VERSION ""

NS_ :

BS_:

BU_: XXX 0

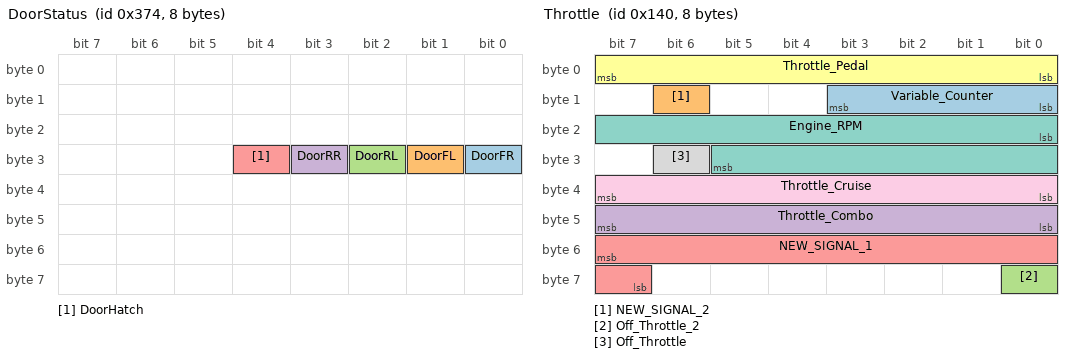
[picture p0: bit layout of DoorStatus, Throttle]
BO_ 884 DoorStatus: 8 XXX
 SG_ DoorFR : 24|1@0+ (1,0) [0|1] "" XXX
 SG_ DoorFL : 25|1@0+ (1,0) [0|1] "" XXX
 SG_ DoorRL : 26|1@0+ (1,0) [0|1] "" XXX
 SG_ DoorRR : 27|1@0+ (1,0) [0|1] "" XXX
 SG_ DoorHatch : 28|1@0+ (1,0) [0|1] "" XXX

BO_ 324 CruiseControl: 8 XXX
 SG_ NEW_SIGNAL_7 : 4|1@0+ (1,0) [0|3] "" XXX
 SG_ NEW_SIGNAL_3 : 4|1@0+ (1,0) [0|15] "" XXX
 SG_ CRUISE_SET : 3|1@0+ (1,0) [0|3] "" XXX
 SG_ NEW_SIGNAL_2 : 8|1@0+ (1,0) [0|255] "" XXX
 SG_ NEW_SIGNAL_9 : 15|1@1+ (1,0) [0|127] "" XXX
 SG_ NEW_SIGNAL_1 : 23|8@0+ (1,0) [0|255] "" XXX
 SG_ NEW_SIGNAL_6 : 50|1@0+ (1,0) [0|3] "" XXX
 SG_ Cruise_On : 48|1@0+ (1,0) [0|3] "" XXX
 SG_ OnOff : 2|1@1+ (1,0) [0|3] "" XXX
 SG_ NEW_SIGNAL_4 : 51|1@0+ (1,0) [0|3] "" XXX

BO_ 320 Throttle: 8 XXX
 SG_ Variable_Counter : 8|4@1+ (1,0) [0|15] "" XXX
 SG_ NEW_SIGNAL_2 : 14|1@0+ (1,0) [0|15] "" XXX
 SG_ Off_Throttle_2 : 56|1@1+ (1,0) [0|3] "" XXX
 SG_ Throttle_Combo : 40|8@1+ (1,0) [0|255] "" XXX
 SG_ NEW_SIGNAL_1 : 55|9@0+ (1,0) [0|255] "" XXX
 SG_ Throttle_Pedal : 0|8@1+ (0.392157,0) [0|255] "" XXX
 SG_ Engine_RPM : 16|14@1+ (1,0) [0|15] "" XXX
 SG_ Off_Throttle : 30|1@0+ (1,0) [0|3] "" XXX
 SG_ Throttle_Cruise : 39|8@0+ (1,0) [0|255] "" XXX

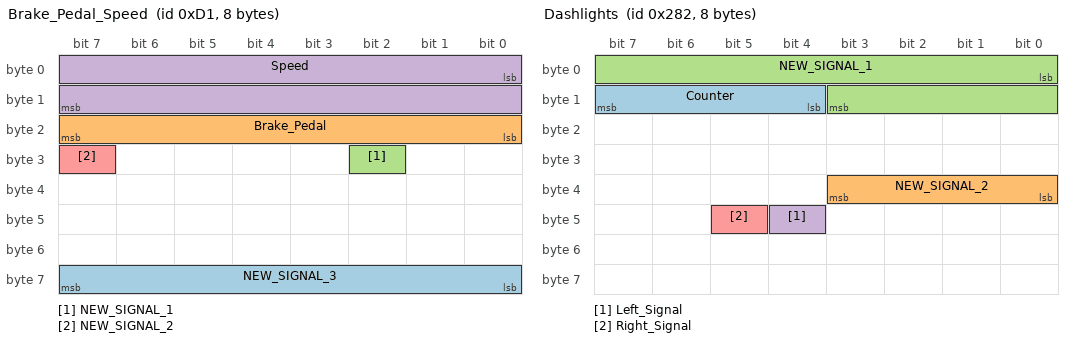
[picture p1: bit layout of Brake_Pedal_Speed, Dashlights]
BO_ 209 Brake_Pedal_Speed: 8 XXX
 SG_ NEW_SIGNAL_3 : 56|8@1+ (1,0) [0|255] "" XXX
 SG_ Brake_Pedal : 23|8@0+ (1,0) [0|255] "" XXX
 SG_ NEW_SIGNAL_1 : 26|1@1+ (1,0) [0|3] "" XXX
 SG_ Speed : 0|16@1+ (1,0) [0|255] "KPH" XXX
 SG_ NEW_SIGNAL_2 : 31|1@1+ (1,0) [0|255] "" XXX

BO_ 2 Steering: 8 XXX
 SG_ NEW_SIGNAL_1 : 31|4@0- (1,0) [0|65535] "" XXX
 SG_ SteeringAngle : 7|16@0- (0.1,0) [-497|500] "degree" XXX
 SG_ NEW_SIGNAL_3 : 33|3@1+ (1,0) [0|15] "" XXX
 SG_ NEW_SIGNAL_2 : 36|4@1+ (1,0) [0|255] "" XXX
 SG_ NEW_SIGNAL_4 : 32|1@1+ (1,0) [0|3] "" XXX
 SG_ NEW_SIGNAL_5 : 37|2@0+ (1,0) [0|3] "" XXX
 SG_ NEW_SIGNAL_6 : 24|1@1+ (1,0) [0|3] "" XXX
 SG_ Counter : 25|3@1+ (1,0) [0|15] "" XXX

BO_ 642 Dashlights: 8 XXX
 SG_ Counter : 15|4@0+ (1,0) [0|15] "" XXX
 SG_ NEW_SIGNAL_2 : 32|4@1+ (1,0) [0|15] "" XXX
 SG_ NEW_SIGNAL_1 : 0|12@1+ (1,0) [0|255] "" XXX
 SG_ Left_Signal : 44|1@0+ (1,0) [0|3] "" XXX
 SG_ Right_Signal : 45|1@0+ (1,0) [0|3] "" XXX

BO_ 112 Lateral_G: 8 XXX
 SG_ Lateral_G : 8|8@1+ (1,0) [0|15] "" XXX

BO_ 882 ES_Counter: 8 XXX
 SG_ Counter : 15|4@0+ (1,0) [0|31] "" XXX
 SG_ NEW_SIGNAL_1 : 30|1@0+ (1,0) [0|3] "" XXX

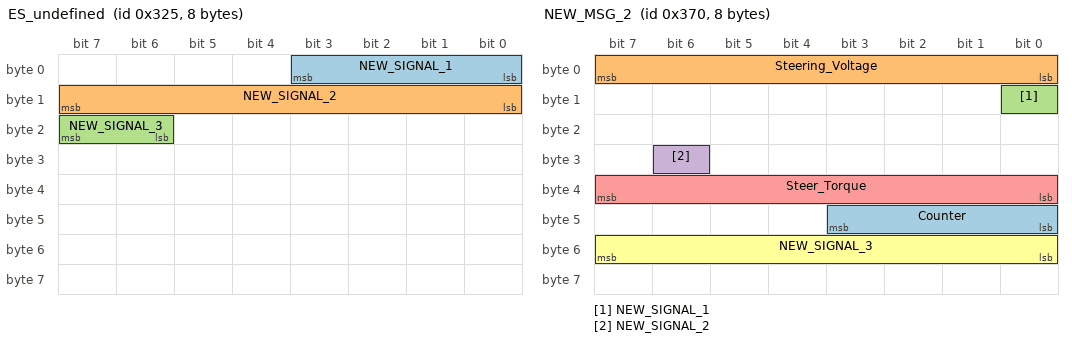
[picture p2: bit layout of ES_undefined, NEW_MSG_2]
BO_ 805 ES_undefined: 8 XXX
 SG_ NEW_SIGNAL_1 : 0|4@1+ (1,0) [0|15] "" XXX
 SG_ NEW_SIGNAL_2 : 8|8@1+ (1,0) [0|255] "" XXX
 SG_ NEW_SIGNAL_3 : 23|2@0+ (1,0) [0|3] "" XXX

BO_ 604 undefined: 8 XXX
 SG_ NEW_SIGNAL_1 : 33|1@1+ (1,0) [0|3] "" XXX
 SG_ NEW_SIGNAL_3 : 43|1@0+ (1,0) [0|3] "" XXX

BO_ 886 undefined: 8 XXX

BO_ 880 NEW_MSG_2: 8 XXX
 SG_ Counter : 40|4@1+ (1,0) [0|15] "" XXX
 SG_ Steering_Voltage : 7|8@0+ (1,0) [0|255] "" XXX
 SG_ NEW_SIGNAL_1 : 8|1@0+ (1,0) [0|255] "" XXX
 SG_ NEW_SIGNAL_2 : 30|1@0+ (1,0) [0|3] "" XXX
 SG_ Steer_Torque : 39|8@0- (1,0) [0|255] "" XXX
 SG_ NEW_SIGNAL_3 : 48|8@1+ (1,0) [0|15] "" XXX

BO_ 554 NEW_MSG_3: 8 XXX
 SG_ Counter : 0|4@1+ (1,0) [0|255] "" XXX

BO_ 355 NEW_MSG_4: 8 XXX
 SG_ Counter : 40|3@1+ (1,0) [0|7] "" XXX

BO_ 1398 NEW_MSG_5: 8 XXX
 SG_ NEW_SIGNAL_2 : 23|8@0+ (1,0) [0|255] "" XXX
 SG_ NEW_SIGNAL_1 : 39|8@0+ (1,0) [0|255] "" XXX
 SG_ NEW_SIGNAL_3 : 39|4@0+ (1,0) [0|15] "" XXX
 SG_ Steer_Torque : 0|8@1+ (1,0) [0|15] "" XXX
 SG_ NEW_SIGNAL_4 : 47|8@0+ (1,0) [0|65535] "" XXX
 SG_ NEW_SIGNAL_5 : 48|8@1+ (1,0) [0|255] "" XXX

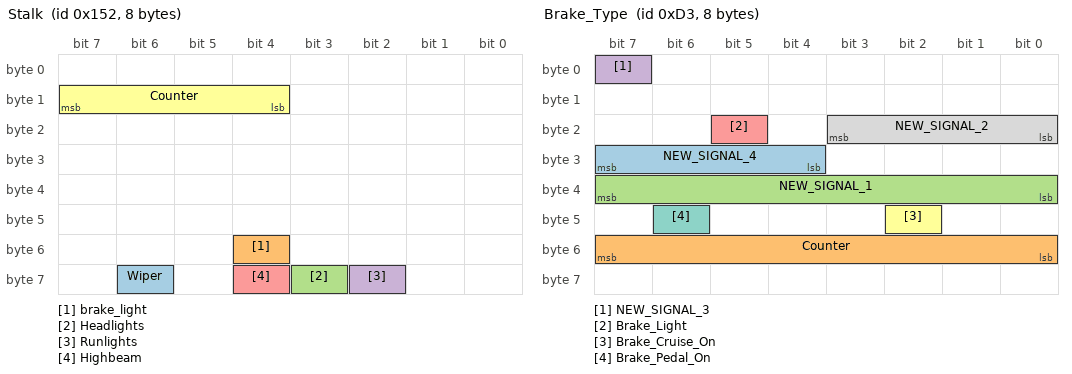
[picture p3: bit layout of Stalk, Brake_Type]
BO_ 338 Stalk: 8 XXX
 SG_ Wiper : 62|1@0+ (1,0) [0|3] "" XXX
 SG_ brake_light : 52|1@0+ (1,0) [0|3] "" XXX
 SG_ Headlights : 59|1@0+ (1,0) [0|3] "" XXX
 SG_ Runlights : 58|1@1+ (1,0) [0|3] "" XXX
 SG_ Highbeam : 60|1@0+ (1,0) [0|3] "" XXX
 SG_ Counter : 15|4@0+ (1,0) [0|15] "" XXX

BO_ 211 Brake_Type: 8 XXX
 SG_ NEW_SIGNAL_4 : 28|4@1+ (1,0) [0|15] "" XXX
 SG_ Counter : 55|8@0+ (1,0) [0|255] "" XXX
 SG_ NEW_SIGNAL_1 : 32|8@1+ (1,0) [0|15] "" XXX
 SG_ NEW_SIGNAL_3 : 7|1@0+ (1,0) [0|4294967295] "" XXX
 SG_ Brake_Light : 21|1@0+ (1,0) [0|3] "" XXX
 SG_ Brake_Cruise_On : 42|1@0+ (1,0) [0|3] "" XXX
 SG_ Brake_Pedal_On : 46|1@0+ (1,0) [0|3] "" XXX
 SG_ NEW_SIGNAL_2 : 16|4@1+ (1,0) [0|15] "" XXX

BO_ 321 undefined: 8 XXX
 SG_ NEW_SIGNAL_1 : 0|16@1+ (1,0) [0|255] "" XXX
 SG_ NEW_SIGNAL_4 : 16|16@1+ (1,0) [0|255] "" XXX
 SG_ NEW_SIGNAL_7 : 59|2@1+ (1,0) [0|63] "" XXX
 SG_ NEW_SIGNAL_8 : 32|12@1+ (1,0) [0|8191] "" XXX
 SG_ NEW_SIGNAL_6 : 46|1@0+ (1,0) [0|3] "" XXX
 SG_ NEW_SIGNAL_2 : 47|1@1+ (1,0) [0|15] "" XXX
 SG_ NEW_SIGNAL_3 : 54|2@0+ (1,0) [0|255] "" XXX
 SG_ NEW_SIGNAL_5 : 48|4@1+ (1,0) [0|15] "" XXX

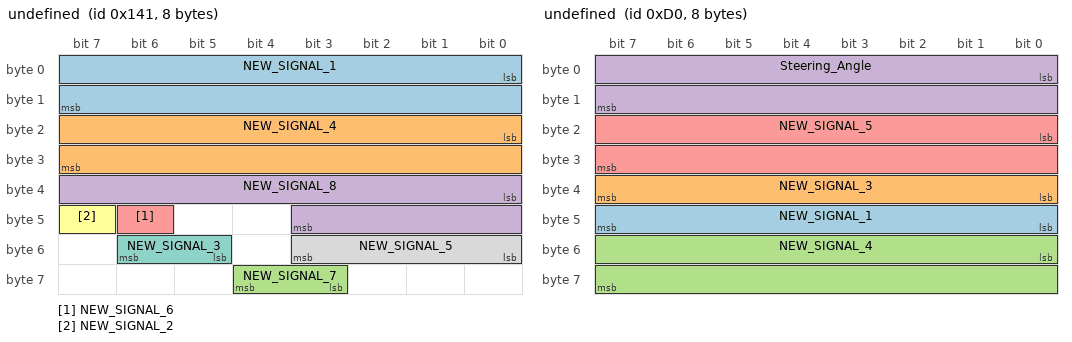
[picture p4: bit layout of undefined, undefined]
BO_ 208 undefined: 8 XXX
 SG_ NEW_SIGNAL_1 : 47|8@0+ (1,0) [0|255] "" XXX
 SG_ NEW_SIGNAL_3 : 32|8@1+ (1,0) [0|255] "" XXX
 SG_ NEW_SIGNAL_4 : 48|16@1- (1,0) [0|255] "" XXX
 SG_ Steering_Angle : 0|16@1- (1,0) [0|65535] "" XXX
 SG_ NEW_SIGNAL_5 : 16|16@1- (1,0) [0|65535] "" XXX

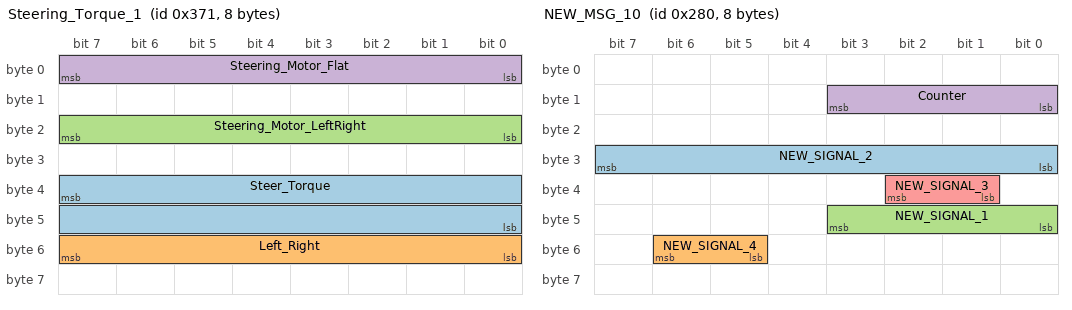
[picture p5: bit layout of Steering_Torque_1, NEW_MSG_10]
BO_ 881 Steering_Torque_1: 8 XXX
 SG_ Steer_Torque : 39|16@0- (1,0) [0|255] "" XXX
 SG_ Left_Right : 55|8@0- (1,0) [0|255] "" XXX
 SG_ Steering_Motor_LeftRight : 23|8@0- (1,0) [0|255] "" XXX
 SG_ Steering_Motor_Flat : 0|8@1+ (1,0) [0|255] "" XXX

BO_ 336 Brake_Pressure: 8 XXX
 SG_ Brake_Pressure_1 : 0|8@1+ (1,0) [0|15] "" XXX
 SG_ Brake_Pressure_2 : 15|8@0+ (1,0) [0|255] "" XXX

BO_ 640 NEW_MSG_10: 8 XXX
 SG_ NEW_SIGNAL_2 : 24|8@1+ (1,0) [0|255] "" XXX
 SG_ NEW_SIGNAL_4 : 54|2@0+ (1,0) [0|15] "" XXX
 SG_ NEW_SIGNAL_1 : 43|4@0+ (1,0) [0|255] "" XXX
 SG_ Counter : 8|4@1+ (1,0) [0|15] "" XXX
 SG_ NEW_SIGNAL_3 : 34|2@0+ (1,0) [0|63] "" XXX

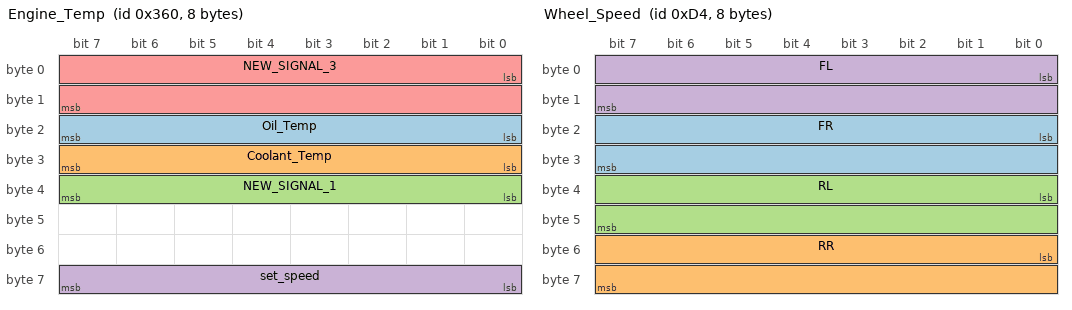
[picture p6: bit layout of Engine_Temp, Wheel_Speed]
BO_ 864 Engine_Temp: 8 XXX
 SG_ Oil_Temp : 16|8@1+ (1,-40) [0|255] "" XXX
 SG_ Coolant_Temp : 24|8@1+ (1,-40) [0|255] "" XXX
 SG_ NEW_SIGNAL_1 : 32|8@1+ (1,0) [0|255] "" XXX
 SG_ set_speed : 56|8@1+ (1,0) [0|63] "" XXX
 SG_ NEW_SIGNAL_3 : 0|16@1+ (1,0) [0|255] "" XXX

BO_ 212 Wheel_Speed: 8 XXX
 SG_ FR : 16|16@1+ (0.05747,0) [0|255] "KPH" XXX
 SG_ RR : 48|16@1+ (0.05747,0) [0|127] "KPH" XXX
 SG_ RL : 32|16@1+ (0.05747,0) [0|255] "" XXX
 SG_ FL : 0|16@1+ (0.05747,0) [2|255] "KPH" XXX

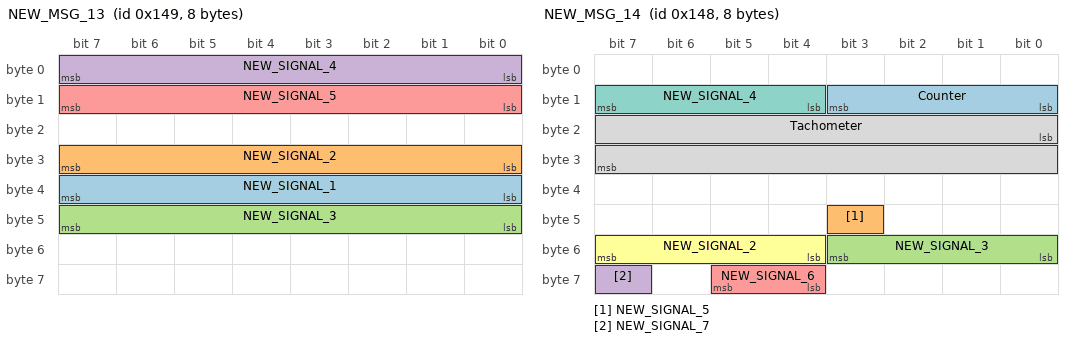
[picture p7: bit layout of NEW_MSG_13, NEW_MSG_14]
BO_ 329 NEW_MSG_13: 8 XXX
 SG_ NEW_SIGNAL_1 : 32|8@1+ (1,0) [0|255] "" XXX
 SG_ NEW_SIGNAL_2 : 31|8@0+ (1,0) [0|255] "" XXX
 SG_ NEW_SIGNAL_3 : 40|8@1+ (1,0) [0|255] "" XXX
 SG_ NEW_SIGNAL_4 : 0|8@1+ (1,0) [0|255] "" XXX
 SG_ NEW_SIGNAL_5 : 15|8@0+ (1,0) [0|65535] "" XXX

BO_ 328 NEW_MSG_14: 8 XXX
 SG_ Counter : 11|4@0+ (1,0) [0|255] "" XXX
 SG_ NEW_SIGNAL_5 : 43|1@0+ (1,0) [0|65535] "" XXX
 SG_ NEW_SIGNAL_3 : 48|4@1+ (1,0) [0|15] "" XXX
 SG_ NEW_SIGNAL_7 : 63|1@0+ (1,0) [0|3] "" XXX
 SG_ NEW_SIGNAL_6 : 60|2@1+ (1,0) [0|255] "" XXX
 SG_ NEW_SIGNAL_2 : 52|4@1+ (1,0) [0|15] "" XXX
 SG_ NEW_SIGNAL_4 : 15|4@0+ (1,0) [0|15] "" XXX
 SG_ Tachometer : 16|16@1+ (1,0) [0|65535] "" XXX

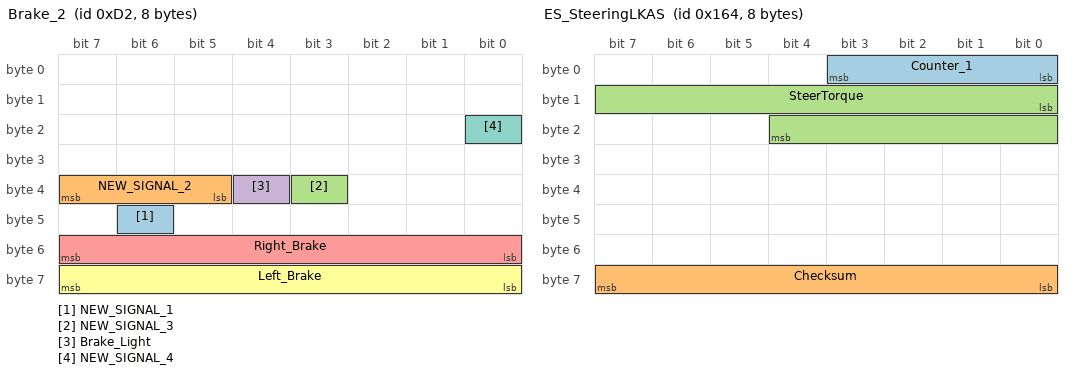
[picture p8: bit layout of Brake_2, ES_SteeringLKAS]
BO_ 210 Brake_2: 8 XXX
 SG_ NEW_SIGNAL_1 : 46|1@0+ (1,0) [0|4294967295] "" XXX
 SG_ NEW_SIGNAL_2 : 39|3@0+ (1,0) [0|7] "" XXX
 SG_ NEW_SIGNAL_3 : 35|1@1+ (1,0) [0|15] "" XXX
 SG_ Brake_Light : 36|1@1+ (1,0) [0|255] "" XXX
 SG_ Right_Brake : 48|8@1+ (1,0) [0|255] "" XXX
 SG_ Left_Brake : 63|8@0+ (1,0) [0|255] "" XXX
 SG_ NEW_SIGNAL_4 : 16|1@0+ (1,0) [0|1] "" XXX

BO_ 346 Counter_3: 8 XXX
 SG_ Counter : 0|4@1+ (1,0) [0|15] "" XXX

BO_ 356 ES_SteeringLKAS: 8 XXX
 SG_ Counter_1 : 0|4@1+ (1,0) [0|15] "" XXX
 SG_ Checksum : 56|8@1+ (1,0) [0|15] "" XXX
 SG_ SteerTorque : 8|13@1- (1,0) [0|65535] "" XXX

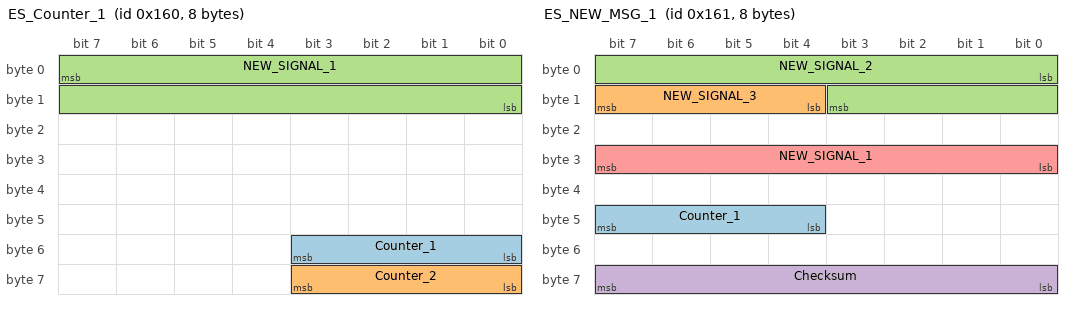
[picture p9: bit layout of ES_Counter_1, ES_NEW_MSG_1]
BO_ 352 ES_Counter_1: 8 XXX
 SG_ Counter_1 : 48|4@1+ (1,0) [0|15] "" XXX
 SG_ Counter_2 : 59|4@0+ (1,0) [0|4095] "" XXX
 SG_ NEW_SIGNAL_1 : 7|16@0+ (1,0) [0|65535] "" XXX

BO_ 392 Counter_0: 8 XXX
 SG_ Counter : 16|4@1+ (1,0) [0|15] "" XXX

BO_ 353 ES_NEW_MSG_1: 8 XXX
 SG_ Counter_1 : 47|4@0+ (1,0) [0|15] "" XXX
 SG_ NEW_SIGNAL_3 : 15|4@0+ (1,0) [0|15] "" XXX
 SG_ NEW_SIGNAL_2 : 0|12@1+ (1,0) [0|255] "" XXX
 SG_ Checksum : 56|8@1+ (1,0) [0|15] "" XXX
 SG_ NEW_SIGNAL_1 : 24|8@1+ (1,0) [0|3] "" XXX

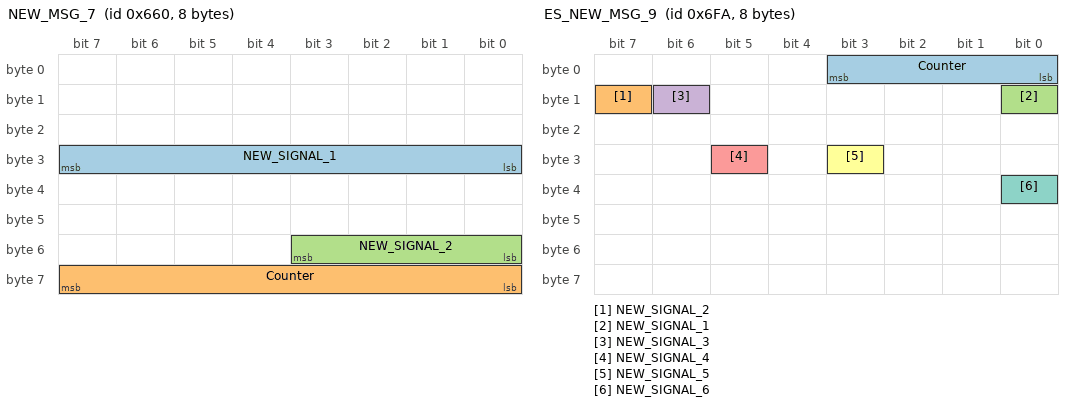
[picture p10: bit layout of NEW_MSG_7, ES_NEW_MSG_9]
BO_ 1632 NEW_MSG_7: 8 XXX
 SG_ NEW_SIGNAL_1 : 31|8@0+ (1,0) [0|255] "" XXX
 SG_ Counter : 56|8@1+ (1,0) [0|255] "" XXX
 SG_ NEW_SIGNAL_2 : 51|4@0+ (1,0) [0|16777215] "" XXX

BO_ 644 NEW_MSG_8: 8 XXX
 SG_ Counter : 8|4@1+ (1,0) [0|15] "" XXX

BO_ 1786 ES_NEW_MSG_9: 8 XXX
 SG_ Counter : 3|4@0+ (1,0) [0|255] "" XXX
 SG_ NEW_SIGNAL_2 : 15|1@1+ (1,0) [0|15] "" XXX
 SG_ NEW_SIGNAL_1 : 8|1@1+ (1,0) [0|3] "" XXX
 SG_ NEW_SIGNAL_3 : 14|1@0+ (1,0) [0|3] "" XXX
 SG_ NEW_SIGNAL_4 : 29|1@0+ (1,0) [0|1] "" XXX
 SG_ NEW_SIGNAL_5 : 27|1@1+ (1,0) [0|3] "" XXX
 SG_ NEW_SIGNAL_6 : 32|1@1+ (1,0) [0|3] "" XXX

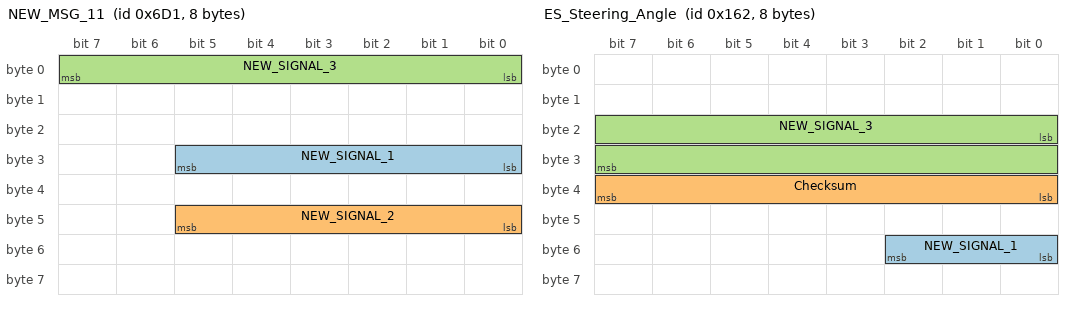
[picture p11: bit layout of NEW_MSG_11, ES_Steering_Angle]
BO_ 1745 NEW_MSG_11: 8 XXX
 SG_ NEW_SIGNAL_1 : 24|6@1+ (1,0) [0|255] "" XXX
 SG_ NEW_SIGNAL_2 : 40|6@1+ (1,0) [0|15] "" XXX
 SG_ NEW_SIGNAL_3 : 0|8@1+ (1,0) [0|255] "" XXX

BO_ 977 NEW_MSG_12: 8 XXX
 SG_ NEW_SIGNAL_1 : 0|8@1+ (1,0) [0|255] "" XXX
 SG_ NEW_SIGNAL_2 : 16|8@1+ (1,0) [0|255] "" XXX

BO_ 872 NEW_MSG_15: 8 XXX

BO_ 354 ES_Steering_Angle: 8 XXX
 SG_ NEW_SIGNAL_1 : 48|3@1+ (1,0) [0|7] "" XXX
 SG_ Checksum : 39|8@0+ (1,0) [0|255] "" XXX
 SG_ NEW_SIGNAL_3 : 16|16@1+ (1,0) [0|255] "" XXX

BO_ 358 ES_NEW_MSG_1: 8 XXX
 SG_ NEW_SIGNAL_1 : 39|3@0+ (1,0) [0|31] "" XXX
 SG_ NEW_SIGNAL_2 : 35|1@0+ (1,0) [0|1] "" XXX
 SG_ NEW_SIGNAL_3 : 48|4@1+ (1,0) [0|15] "" XXX
 SG_ NEW_SIGNAL_4 : 21|1@0+ (1,0) [0|3] "" XXX
 SG_ NEW_SIGNAL_5 : 20|1@0+ (1,0) [0|3] "" XXX

BO_ 359 ES_NEW_MSG_1: 8 XXX
 SG_ NEW_SIGNAL_1 : 0|1@1+ (1,0) [0|3] "" XXX
 SG_ NEW_SIGNAL_2 : 36|1@0+ (1,0) [0|3] "" XXX
 SG_ NEW_SIGNAL_3 : 24|2@1+ (1,0) [0|3] "" XXX
 SG_ NEW_SIGNAL_4 : 48|5@1+ (1,0) [0|31] "" XXX
 SG_ NEW_SIGNAL_5 : 28|1@0+ (1,0) [0|3] "" XXX
 SG_ NEW_SIGNAL_6 : 31|1@0+ (1,0) [0|3] "" XXX
 SG_ NEW_SIGNAL_7 : 37|1@0+ (1,0) [0|3] "" XXX

BO_ 417018865 ES_NEW_MSG_1: 8 XXX
 SG_ NEW_SIGNAL_1 : 8|1@0+ (1,0) [0|1] "" XXX

BO_ 1640 ES_NEW_MSG_1: 8 XXX
 SG_ NEW_SIGNAL_1 : 8|4@1+ (1,0) [0|255] "" XXX
 SG_ NEW_SIGNAL_2 : 16|4@1+ (1,0) [0|15] "" XXX
 SG_ NEW_SIGNAL_3 : 48|8@1+ (1,0) [0|255] "" XXX
 SG_ NEW_SIGNAL_4 : 45|1@0+ (1,0) [0|3] "" XXX
 SG_ NEW_SIGNAL_5 : 42|1@1+ (1,0) [0|3] "" XXX
 SG_ NEW_SIGNAL_6 : 41|1@1+ (1,0) [0|3] "" XXX
 SG_ NEW_SIGNAL_7 : 43|1@0+ (1,0) [0|3] "" XXX
 SG_ NEW_SIGNAL_8 : 36|1@0+ (1,0) [0|7] "" XXX
 SG_ NEW_SIGNAL_9 : 28|1@0+ (1,0) [0|7] "" XXX
 SG_ NEW_SIGNAL_10 : 14|1@0+ (1,0) [0|3] "" XXX
 SG_ NEW_SIGNAL_11 : 60|1@0+ (1,0) [0|3] "" XXX
 SG_ NEW_SIGNAL_12 : 63|1@0+ (1,0) [0|3] "" XXX
 SG_ NEW_SIGNAL_13 : 59|1@1+ (1,0) [0|7] "" XXX

BO_ 1785 ES_NEW_MSG_1: 8 XXX
 SG_ NEW_SIGNAL_1 : 0|4@1+ (1,0) [0|7] "" XXX

BO_ 1788 NEW_MSG_1: 8 XXX

BO_ 1787 ES_NEW_MSG_1: 8 XXX
 SG_ NEW_SIGNAL_1 : 0|4@1+ (1,0) [0|7] "" XXX
 SG_ NEW_SIGNAL_2 : 15|1@1+ (1,0) [0|255] "" XXX
 SG_ NEW_SIGNAL_3 : 14|1@0+ (1,0) [0|3] "" XXX
 SG_ NEW_SIGNAL_4 : 8|1@1+ (1,0) [0|3] "" XXX
 SG_ NEW_SIGNAL_5 : 27|1@1+ (1,0) [0|7] "" XXX
 SG_ NEW_SIGNAL_6 : 29|1@0+ (1,0) [0|3] "" XXX
 SG_ NEW_SIGNAL_7 : 32|1@1+ (1,0) [0|3] "" XXX

BO_ 1882 ES_NEW_MSG_1: 8 XXX
 SG_ NEW_SIGNAL_1 : 14|7@0+ (1,0) [0|127] "" XXX
 SG_ NEW_SIGNAL_2 : 0|1@1+ (1,0) [0|3] "" XXX
 SG_ NEW_SIGNAL_3 : 1|1@1+ (1,0) [0|3] "" XXX
 SG_ NEW_SIGNAL_4 : 16|1@1+ (1,0) [0|3] "" XXX
 SG_ NEW_SIGNAL_5 : 24|1@1+ (1,0) [0|3] "" XXX
 SG_ NEW_SIGNAL_6 : 28|1@0+ (1,0) [0|3] "" XXX

BO_ 2015 ES_NEW_MSG_1: 8 XXX
 SG_ NEW_SIGNAL_1 : 16|6@1+ (1,0) [0|63] "" XXX

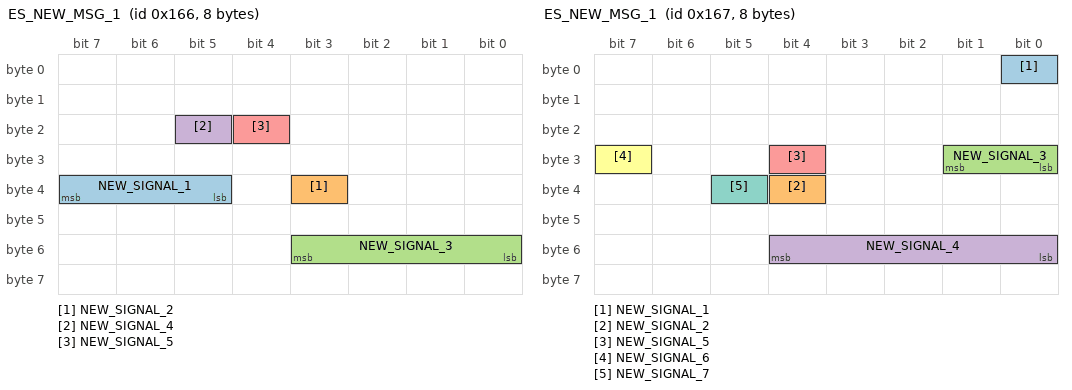
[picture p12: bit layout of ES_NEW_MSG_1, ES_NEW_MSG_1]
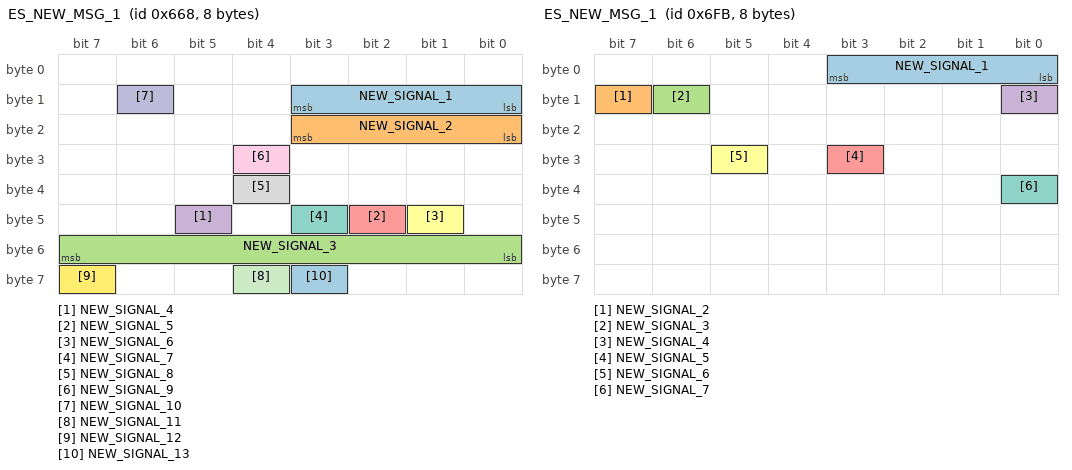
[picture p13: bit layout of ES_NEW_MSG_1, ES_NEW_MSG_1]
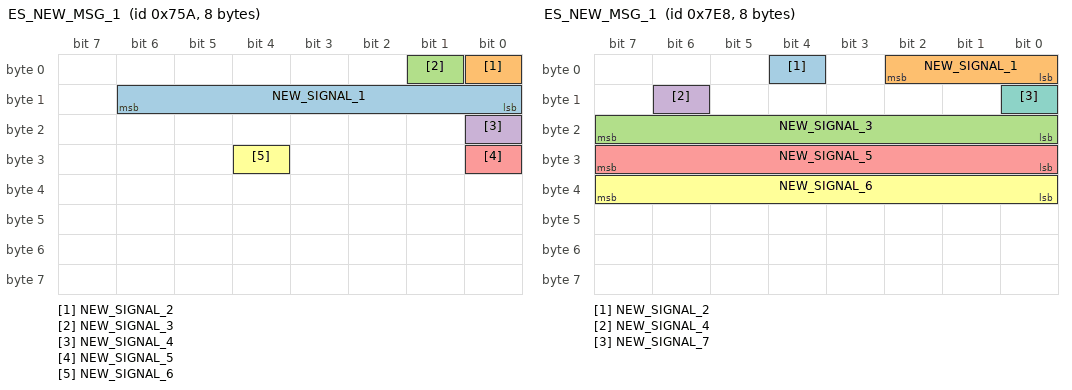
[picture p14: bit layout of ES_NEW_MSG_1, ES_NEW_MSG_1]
BO_ 2024 ES_NEW_MSG_1: 8 XXX
 SG_ NEW_SIGNAL_2 : 4|1@0+ (1,0) [0|3] "" XXX
 SG_ NEW_SIGNAL_1 : 2|3@0+ (1,0) [0|255] "" XXX
 SG_ NEW_SIGNAL_3 : 23|8@0+ (1,0) [0|255] "" XXX
 SG_ NEW_SIGNAL_4 : 14|1@0+ (1,0) [0|255] "" XXX
 SG_ NEW_SIGNAL_5 : 31|8@0+ (1,0) [0|255] "" XXX
 SG_ NEW_SIGNAL_6 : 39|8@0+ (1,0) [0|127] "" XXX
 SG_ NEW_SIGNAL_7 : 8|1@1+ (1,0) [0|3] "" XXX

CM_ SG_ 320 Off_Throttle_2 "Less sensitive than first";
CM_ SG_ 320 NEW_SIGNAL_1 "Throttle related";
CM_ SG_ 642 Right_Signal "0 off, 2 right, 1 left";
CM_ SG_ 880 Steering_Voltage "Something to do with turning";
CM_ SG_ 338 Wiper "0 off, 1 on";
CM_ SG_ 881 Left_Right "Missing extra larger bits";
CM_ SG_ 881 Steering_Motor_Flat "Possibly motor voltage";
CM_ SG_ 212 RL "KPH";
VAL_ 642 Right_Signal 2 "Left" 1 "Right" ;
CM_ "CHFFR_METRIC 2 STEER_ANGLE STEER_ANGLE 0.36 180";
